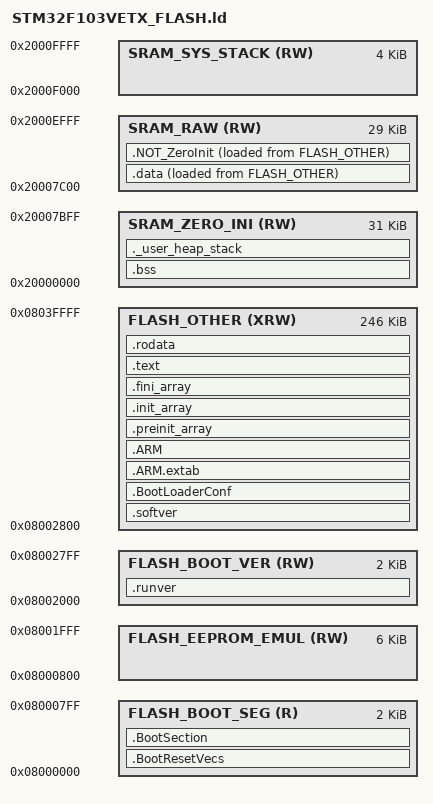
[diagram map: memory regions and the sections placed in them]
/*
******************************************************************************
**
** @file        : LinkerScript.ld
**
** @author      : Auto-generated by STM32CubeIDE
**
** @brief       : Linker script for STM32F103VETx Device from STM32F1 series
**                      512KBytes FLASH
**                      64KBytes RAM
**
**                Set heap size, stack size and stack location according
**                to application requirements.
**
**                Set memory bank area and size if external memory is used
**
**  Target      : STMicroelectronics STM32
**
**  Distribution: The file is distributed as is, without any warranty
**                of any kind.
**
******************************************************************************
** @attention
**
** Copyright (c) 2024 STMicroelectronics.
** All rights reserved.
**
** This software is licensed under terms that can be found in the LICENSE file
** in the root directory of this software component.
** If no LICENSE file comes with this software, it is provided AS-IS.
**
******************************************************************************
*/

/* Entry Point */
ENTRY(Reset_Handler)

/* Highest address of the user mode stack */
_estack = ORIGIN(SRAM_SYS_STACK) + LENGTH(SRAM_SYS_STACK); /* end of "RAM" Ram type memory */

/* VTOR start address */
_svtor = ORIGIN(FLASH_BOOT_SEG);

_Min_Heap_Size = 0x200; /* required amount of heap */
_Min_Stack_Size = 0x400; /* required amount of stack */

_flashBankOffset = 0;						/* A bank version soft offset���ϰ��256K */
//_flashBankOffset = 0x40000;				/* B bank version soft offset���°��256K */
  	
/* Memories definition */
MEMORY
{
  	FLASH_BOOT_SEG		(R)		: ORIGIN = 0x8000000 + _flashBankOffset,	LENGTH = 2K
	FLASH_EEPROM_EMUL	(RW)	: ORIGIN = 0x8000800 + _flashBankOffset,	LENGTH = 6K
	FLASH_BOOT_VER		(RW)	: ORIGIN = 0x8002000 + _flashBankOffset,	LENGTH = 2K		
  	FLASH_OTHER    		(XRW)   : ORIGIN = 0x8002800 + _flashBankOffset,	LENGTH = 246K
  
	SRAM_ZERO_INI 		(RW) 	: ORIGIN = 0x20000000, 	LENGTH = 31K	
    SRAM_RAW 			(RW) 	: ORIGIN = 0x20007C00, 	LENGTH = 29K	
   	SRAM_SYS_STACK		(RW)	: ORIGIN = 0x2000F000, 	LENGTH = 4K	
}

/* Sections */
SECTIONS
{
  /* The startup code into "FLASH" Rom type memory */
  /* FLASH_BOOT_SEG =======================================================================================================================*/
  . = ALIGN(4);
  .BootResetVecs :
  {
    . = ALIGN(4);
    KEEP(*(.BootResetVecs)) 	/* VTOR */
    . = ALIGN(4);
  } >FLASH_BOOT_SEG

  . = ALIGN(4);
  .BootSection :
  {
    . = ALIGN(4);
    KEEP(*(.BootSection))		/* Startup code */ 		
    . = ALIGN(4);
  } >FLASH_BOOT_SEG
  
  /* FLASH_EEPROM_EMUL ================================================================================================================*/
  /* ?? */	
	
  /* FLASH_BOOT_VER  =======================================================================================================================*/
  /* The program code and other data into "FLASH" Rom type memory */
  .runver :
  {
    . = ALIGN(4);
     *(.runver)           /* .softver section */
    KEEP (*(.runver))
    . = ALIGN(4);
  } >FLASH_BOOT_VER

  /* FLASH_OTHER =======================================================================================================================*/
  /* The program code and other data into "FLASH" Rom type memory */
  .softver :
  {
    . = ALIGN(4);
     *(.softver)           /* .softver section  */
    KEEP (*(.softver))
    . = ALIGN(4);
  } >FLASH_OTHER
  
    . = ALIGN(4);
  .BootLoaderConf :
  {
    . = ALIGN(4);
    KEEP(*(.BootLoaderConf))	/* BootLoaderConf */ 		
    . = ALIGN(4);
  } >FLASH_OTHER
  
    . = ALIGN(4);
  .ARM.extab   : {
    . = ALIGN(4);
    *(.ARM.extab* .gnu.linkonce.armextab.*)
    . = ALIGN(4);
  } >FLASH_OTHER

  . = ALIGN(4);
  .ARM : {
    . = ALIGN(4);
    __exidx_start = .;
    *(.ARM.exidx*)
    __exidx_end = .;
    . = ALIGN(4);
  } >FLASH_OTHER

  . = ALIGN(4);
  .preinit_array     :
  {
    . = ALIGN(4);
    PROVIDE_HIDDEN (__preinit_array_start = .);
    KEEP (*(.preinit_array*))
    PROVIDE_HIDDEN (__preinit_array_end = .);
    . = ALIGN(4);
  } >FLASH_OTHER

  . = ALIGN(4);
  .init_array :
  {
    . = ALIGN(4);
    PROVIDE_HIDDEN (__init_array_start = .);
    KEEP (*(SORT(.init_array.*)))
    KEEP (*(.init_array*))
    PROVIDE_HIDDEN (__init_array_end = .);
    . = ALIGN(4);
  } >FLASH_OTHER

  . = ALIGN(4);
  .fini_array :
  {
    . = ALIGN(4);
    PROVIDE_HIDDEN (__fini_array_start = .);
    KEEP (*(SORT(.fini_array.*)))
    KEEP (*(.fini_array*))
    PROVIDE_HIDDEN (__fini_array_end = .);
    . = ALIGN(4);
  } >FLASH_OTHER
  
  .text :
  {
    . = ALIGN(4);
    *(.text)           /* .text sections (code) */
    *(.text*)          /* .text* sections (code) */
    *(.glue_7)         /* glue arm to thumb code */
    *(.glue_7t)        /* glue thumb to arm code */
    *(.eh_frame)

    KEEP (*(.init))
    KEEP (*(.fini))

    . = ALIGN(4);
    _etext = .;        /* define a global symbols at end of code */
  } >FLASH_OTHER

  . = ALIGN(4);
  /* Constant data into "FLASH" Rom type memory */
  .rodata :
  {
    . = ALIGN(4);
    *(.rodata)         /* .rodata sections (constants, strings, etc.) */
    *(.rodata*)        /* .rodata* sections (constants, strings, etc.) */
    . = ALIGN(4);
  } >FLASH_OTHER

  /* SRAM_ZERO_INI ============================================================================================================================*/
  /* Uninitialized data section into "RAM" Ram type memory */
  .bss :
  {
    /* This is used by the startup in order to initialize the .bss section */
    . = ALIGN(4);
    _sbss = .;         /* define a global symbol at bss start */
    __bss_start__ = _sbss;
    *(.bss)
    *(.bss*)
    *(COMMON)

    . = ALIGN(4);
    _ebss = .;         /* define a global symbol at bss end */
    __bss_end__ = _ebss;
  } >SRAM_ZERO_INI

  . = ALIGN(4);
  /* User_heap_stack section, used to check that there is enough "RAM" Ram  type memory left */
  ._user_heap_stack :
  {
    . = ALIGN(8);
    PROVIDE ( end = . );
    PROVIDE ( _end = . );
    . = . + _Min_Heap_Size;
    . = . + _Min_Stack_Size;
    . = ALIGN(8);
  } >SRAM_ZERO_INI
  
  /* RAW_SRAM ============================================================================================================================*/
  /* Used by the startup to initialize data */
  _sidata = LOADADDR(.data);	/* LOADADDR() == VMA(flash) */

  /* Initialized data sections into "RAM" Ram type memory */
  .data :
  {
    . = ALIGN(4);
    _sdata = .;        /* create a global symbol at data start */
    *(.data)           /* .data sections */
    *(.data*)          /* .data* sections */
    *(.RamFunc)        /* .RamFunc sections */
    *(.RamFunc*)       /* .RamFunc* sections */

    . = ALIGN(4);
    _edata = .;        /* define a global symbol at data end */
  } >SRAM_RAW AT> FLASH_OTHER
  
  . = ALIGN(4);
  .NOT_ZeroInit :
  {
    . = ALIGN(4);
    *(.NOT_ZeroInit)
    *(.NOT_ZeroInit*)
    . = ALIGN(4);
  } >SRAM_RAW AT> FLASH_OTHER
  
  /* Remove information from the compiler libraries */
  /DISCARD/ :
  {
    libc.a ( * )
    libm.a ( * )
    libgcc.a ( * )
  }

  .ARM.attributes 0 : { *(.ARM.attributes) }
}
